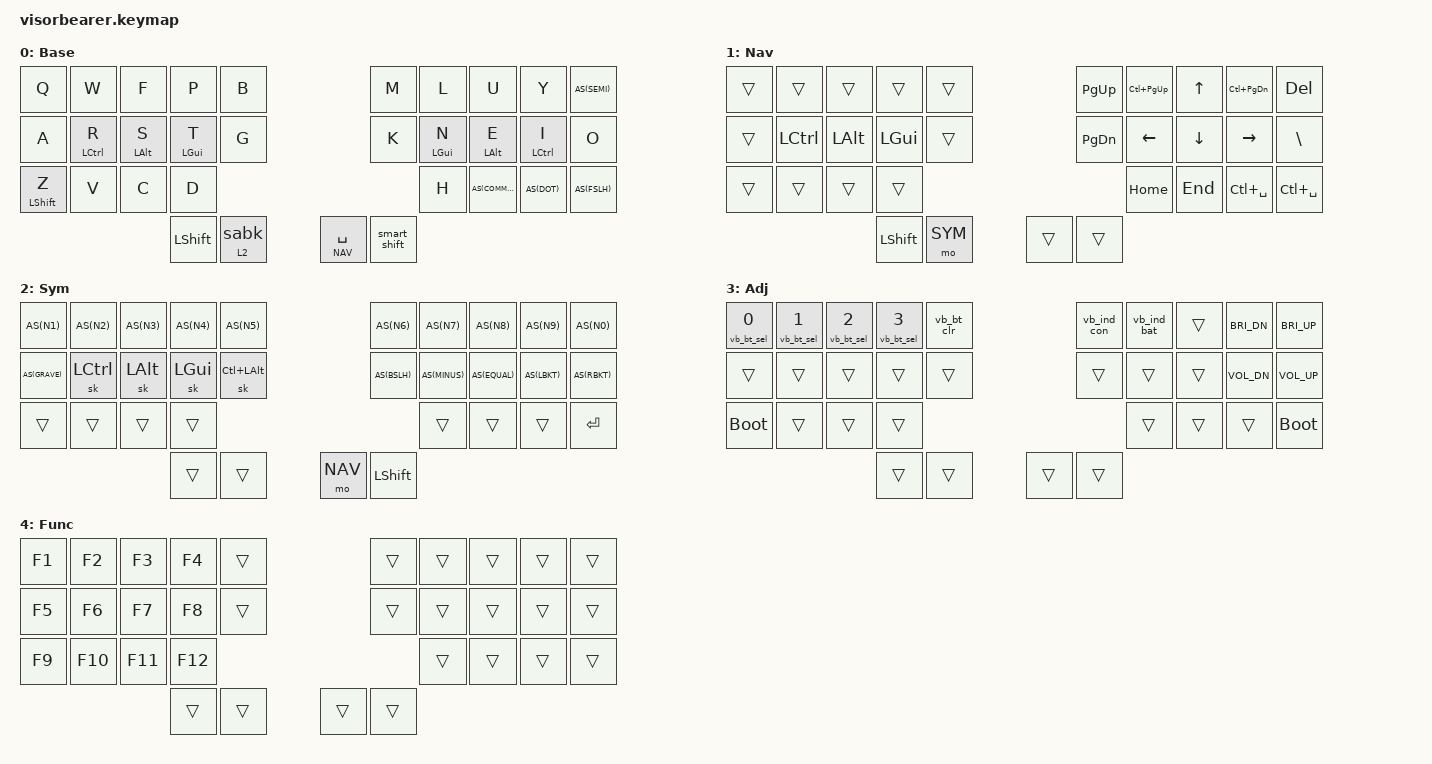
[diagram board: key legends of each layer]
#include <behaviors.dtsi>
#include <dt-bindings/zmk/keys.h>
#include <dt-bindings/zmk/bt.h>
#include <dt-bindings/zmk/outputs.h>
#include <behaviors/visorbearer_led.dtsi>

#define BASE 0
#define NAV  1
#define SYM  2
#define ADJ  3
#define FNC  4

#define AS(keycode) &as LS(keycode) keycode     // Autoshift Macro
#define MEH LS(LC(LALT))

/ {
    behaviors {
        as: auto_shift {
            compatible = "zmk,behavior-hold-tap";
            #binding-cells = <2>;
            tapping_term_ms = <250>;
            // quick_tap_ms = <0>;
            require-prior-idle-ms = <100>;
            flavor = "tap-preferred";
            bindings = <&kp>, <&kp>;
        };
        ht: hold_tap {
            compatible = "zmk,behavior-hold-tap";
            #binding-cells = <2>;
            tapping_term_ms = <200>;
            flavor = "balanced";
            bindings = <&kp>, <&kp>;
        };
        sabk: shift_to_alt_backspace {
            compatible = "zmk,behavior-mod-morph";
            #binding-cells = <0>;
            bindings = <&kp BSPC>, <&kp LA(BSPC)>;
            mods = <(MOD_LSFT|MOD_RSFT)>;
        };
        smart_shift: smart_shift {
            compatible = "zmk,behavior-mod-morph";
            #binding-cells = <0>;
            bindings = <&sk LSHFT>, <&caps_word>;
            mods = <(MOD_LSFT|MOD_RSFT)>;
        };
        sym_bspc: left_thumb_hold_tap {
            compatible = "zmk,behavior-hold-tap";
            #binding-cells = <2>;
            flavor = "tap-preferred";
            tapping-term-ms = <150>;
            quick-tap-ms = <200>;
            bindings = <&mo>, <&sabk>;
        };
        hrm: alpha_hold_tap {
            compatible = "zmk,behavior-hold-tap";
            #binding-cells = <2>;
            flavor = "balanced";
            tapping-term-ms = <280>;
            quick-tap-ms = <175>;
            require-prior-idle-ms = <150>;
            bindings = <&kp>, <&kp>;
        };
        lhm: left_homerow_mods {
            compatible = "zmk,behavior-hold-tap";
            #binding-cells = <2>;
            flavor = "balanced";
            tapping-term-ms = <200>;
            quick-tap-ms = <125>;
            require-prior-idle-ms = <150>;
            bindings = <&kp>, <&kp>;
            hold-trigger-key-positions = <5 6 7 8 9 15 16 17 18 19 24 25 26 27 28 29 30 31>;
        };
        rhm: right_homerow_mods {
            compatible = "zmk,behavior-hold-tap";
            #binding-cells = <2>;
            flavor = "balanced";
            tapping-term-ms = <200>;
            quick-tap-ms = <125>;
            require-prior-idle-ms = <150>;
            bindings = <&kp>, <&kp>;
            hold-trigger-key-positions = <0 1 2 3 4 10 11 12 13 14 20 21 22 23 28 29 30 31>;
        };
    };

    combos {
        compatible = "zmk,combos";
        // missing keys
        fp_j {
            timeout-ms = <50>;
            key-positions = <2 3>;
            bindings = <&kp J>;
        };
        vd_x {
            timeout-ms = <50>;
            key-positions = <21 23>;
            bindings = <&kp X>;
        };

        // tab and escape
        qa_tab {
            timeout-ms = <75>;
            key-positions = <0 10>;
            bindings = <&kp TAB>;
        };
        az_esc {
            timeout-ms = <75>;
            key-positions = <10 20>;
            bindings = <&kp ESC>;
        };

        // brackets
        // square brackets []
        wr_lbkt {
            timeout-ms = <50>;
            key-positions = <1 11>;
            bindings = <&kp LBKT>;
        };
        fs_lbrc {
            timeout-ms = <50>;
            key-positions = <2 12>;
            bindings = <&kp LBRC>;
        };
        // curly brackets {};
        ue_rbrc {
            timeout-ms = <50>;
            key-positions = <7 17>;
            bindings = <&kp RBRC>;
        };
        yi_rbkt {
            timeout-ms = <50>;
            key-positions = <8 18>;
            bindings = <&kp RBKT>;
        };
        // parenthesis ()
        pt_lpar {
            timeout-ms = <50>;
            key-positions = <3 13>;
            bindings = <&kp LPAR>;
        };
        ln_rpar {
            timeout-ms = <50>;
            key-positions = <6 16>;
            bindings = <&kp RPAR>;
        };
        // angled brackets <>
        bg_lt {
            timeout-ms = <50>;
            key-positions = <4 14>;
            bindings = <&kp LT>;
        };
        mk_gt {
            timeout-ms = <50>;
            key-positions = <5 15>;
            bindings = <&kp GT>;
        };

        // thumb combos
        l_thumb {
            timeout-ms = <50>;
            key-positions = <28 29>;
            bindings = <&sl FNC>;
        };
        r_thumb {
            timeout-ms = <50>;
            key-positions = <30 31>;
            bindings = <&sl FNC>;
        };

        semi_o_sqt {
            timeout-ms = <75>;
            key-positions = <9 19>;
            bindings = <&kp SQT>;
        };
        bottomrightcorner_enter {
            timeout-ms = <75>;
            key-positions = <26 27>;
            bindings = <&kp ENTER>;
        };
    };

    conditional_layers {
        compatible = "zmk,conditional-layers";
        tri_layer {
            if-layers = <1 2>;
            then-layer = <3>;
        };
    };

    keymap {
        compatible = "zmk,keymap";

        base {
            display-name = "Base";
            bindings = <
            &kp Q           &kp W           &kp F           &kp P           &kp B                                           &kp M           &kp L           &kp U           &kp Y           AS(SEMI)
            &kp A           &lhm LCTRL R    &lhm LALT S     &lhm LGUI T     &kp G                                           &kp K           &rhm LGUI N     &rhm LALT E     &rhm LCTRL I    &kp O
            &lhm LSHFT Z    &kp V           &kp C           &kp D                                                                           &kp H           AS(COMMA)       AS(DOT)         AS(FSLH)
                                                            &kp LSHFT       &sym_bspc 2 0                   &lt NAV SPACE   &smart_shift
            >;
        };

        nav {
            display-name = "Nav";
            bindings = <
            &trans          &trans          &trans          &trans          &trans                                          &kp PAGE_UP     &kp LC(PG_UP)   &kp UP          &kp LC(PG_DN)   &kp DELETE
            &trans          &kp LCTRL       &kp LALT        &kp LGUI        &trans                                          &kp PAGE_DOWN   &kp LEFT        &kp DOWN        &kp RIGHT       &kp BSLH
            &trans          &trans          &trans          &trans                                                                          &kp HOME        &kp END         &kp LC(SPACE)   &kp LC(SPACE)
                                                                            &kp LSHFT       &mo SYM         &trans          &trans
            >;
        };

        sym {
            display-name = "Sym";
            bindings = <
            AS(N1)          AS(N2)          AS(N3)          AS(N4)          AS(N5)                                          AS(N6)          AS(N7)          AS(N8)          AS(N9)          AS(N0)
            AS(GRAVE)       &sk LCTRL       &sk LALT        &sk LGUI        &sk LC(LALT)                                    AS(BSLH)        AS(MINUS)       AS(EQUAL)       AS(LBKT)        AS(RBKT)
            &trans          &trans          &trans          &trans                                                                          &trans          &trans          &trans          &kp ENTER
                                                                            &trans          &trans          &mo NAV         &kp LSHFT
            >;
        };

        adj {
            display-name = "Adj";
            bindings = <
            &vb_bt_sel 0    &vb_bt_sel 1    &vb_bt_sel 2    &vb_bt_sel 3    &vb_bt_clr                                      &vb_ind_con     &vb_ind_bat     &trans          &kp C_BRI_DN    &kp C_BRI_UP
            &trans          &trans          &trans          &trans          &trans                                          &trans          &trans          &trans          &kp C_VOL_DN    &kp C_VOL_UP
            &bootloader     &trans          &trans          &trans                                                                          &trans          &trans          &trans          &bootloader
                                                                            &trans          &trans          &trans          &trans
            >;
        };

        fnc {
            display-name = "Func";
            bindings = <
            &kp F1          &kp F2          &kp F3          &kp F4          &trans                                          &trans          &trans          &trans          &trans          &trans
            &kp F5          &kp F6          &kp F7          &kp F8          &trans                                          &trans          &trans          &trans          &trans          &trans
            &kp F9          &kp F10         &kp F11         &kp F12                                                                         &trans          &trans          &trans          &trans
                                                                            &trans          &trans          &trans          &trans
            >;
        };
    };
};

&lt {
    tapping-term-ms = <150>;
    quick-tap-ms = <200>;
};

&mt {
    quick-tap-ms = <200>;
};

&sk {
    release-after-ms = <500>;
    quick-release;
};

&sl {
    release-after-ms = <500>;
    quick-release;
};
